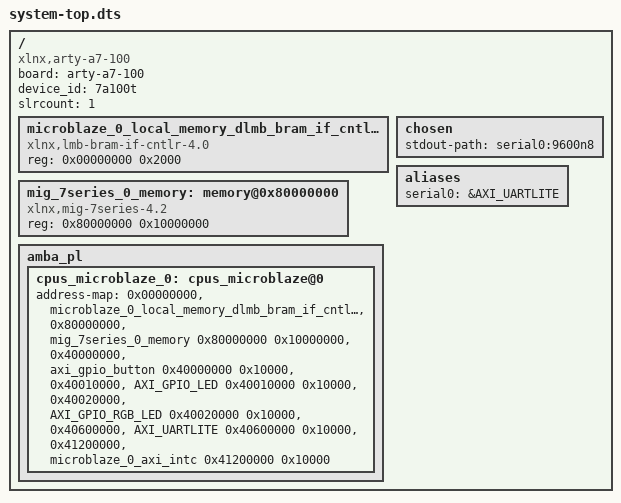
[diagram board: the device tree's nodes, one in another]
/dts-v1/;
#include "pl.dtsi"
/ {
	board = "arty-a7-100";
	compatible = "xlnx,arty-a7-100";
	device_id = "7a100t";
	#address-cells = <1>;
	#size-cells = <1>;
	slrcount = <1>;
	microblaze_0_local_memory_dlmb_bram_if_cntlr_memory: memory@0 {
		compatible = "xlnx,lmb-bram-if-cntlr-4.0";
		device_type = "memory";
		reg = <0x00000000 0x2000>;
	};
	mig_7series_0_memory: memory@0x80000000 {
		compatible = "xlnx,mig-7series-4.2";
		device_type = "memory";
		reg = <0x80000000 0x10000000>;
	};
	chosen {
		stdout-path = "serial0:9600n8";
	};
	aliases {
		serial0 = &AXI_UARTLITE;
	};
	amba_pl: amba_pl {
		cpus_microblaze_0: cpus_microblaze@0 {
			address-map = <0x00000000 &microblaze_0_local_memory_dlmb_bram_if_cntlr_memory 0x00000000 0x2000>, 
			      <0x80000000 &mig_7series_0_memory 0x80000000 0x10000000>, 
			      <0x40000000 &axi_gpio_button 0x40000000 0x10000>, 
			      <0x40010000 &AXI_GPIO_LED 0x40010000 0x10000>, 
			      <0x40020000 &AXI_GPIO_RGB_LED 0x40020000 0x10000>, 
			      <0x40600000 &AXI_UARTLITE 0x40600000 0x10000>, 
			      <0x41200000 &microblaze_0_axi_intc 0x41200000 0x10000>;
			#ranges-address-cells = <0x1>;
			#ranges-size-cells = <0x1>;
		};
	};
};
